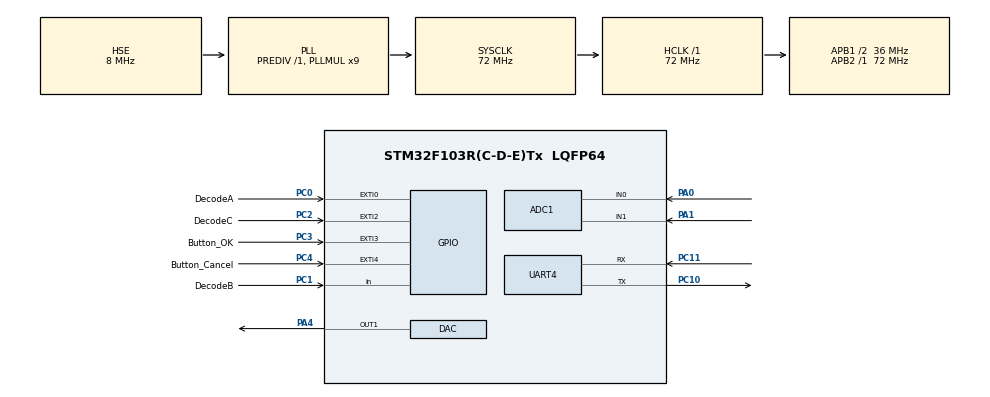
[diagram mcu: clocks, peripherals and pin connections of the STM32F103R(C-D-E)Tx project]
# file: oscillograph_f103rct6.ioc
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ADC1.Channel-0\#ChannelRegularConversion=ADC_CHANNEL_0
ADC1.Channel-1\#ChannelRegularConversion=ADC_CHANNEL_1
ADC1.ExternalTrigConv=ADC_EXTERNALTRIGCONV_T3_TRGO
ADC1.NbrOfConversion=2
ADC1.NbrOfConversionFlag=1
ADC1.Rank-0\#ChannelRegularConversion=1
ADC1.Rank-1\#ChannelRegularConversion=2
ADC1.SamplingTime-0\#ChannelRegularConversion=ADC_SAMPLETIME_1CYCLE_5
ADC1.SamplingTime-1\#ChannelRegularConversion=ADC_SAMPLETIME_1CYCLE_5
ADC1.master=1
DAC.DAC_Trigger=DAC_TRIGGER_T4_TRGO
Dma.ADC1.0.Direction=DMA_PERIPH_TO_MEMORY
Dma.ADC1.0.Instance=DMA1_Channel1
Dma.ADC1.0.MemDataAlignment=DMA_MDATAALIGN_HALFWORD
Dma.ADC1.0.MemInc=DMA_MINC_ENABLE
Dma.ADC1.0.Mode=DMA_CIRCULAR
Dma.ADC1.0.PeriphDataAlignment=DMA_PDATAALIGN_HALFWORD
Dma.ADC1.0.PeriphInc=DMA_PINC_DISABLE
Dma.ADC1.0.Priority=DMA_PRIORITY_LOW
Dma.DAC_CH1.1.Direction=DMA_MEMORY_TO_PERIPH
Dma.DAC_CH1.1.Instance=DMA2_Channel3
Dma.DAC_CH1.1.MemDataAlignment=DMA_MDATAALIGN_HALFWORD
Dma.DAC_CH1.1.MemInc=DMA_MINC_ENABLE
Dma.DAC_CH1.1.Mode=DMA_CIRCULAR
Dma.DAC_CH1.1.PeriphDataAlignment=DMA_PDATAALIGN_HALFWORD
Dma.DAC_CH1.1.PeriphInc=DMA_PINC_DISABLE
Dma.DAC_CH1.1.Priority=DMA_PRIORITY_LOW
Dma.Request0=ADC1
Dma.Request1=DAC_CH1
Mcu.Family=STM32F1
Mcu.Name=STM32F103R(C-D-E)Tx
Mcu.Package=LQFP64
NVIC.ADC1_2_IRQn=true\:0\:0\:false\:false\:true\:true\:true\:true
NVIC.DMA1_Channel1_IRQn=true\:0\:0\:false\:false\:true\:false\:true\:true
NVIC.DMA2_Channel3_IRQn=true\:0\:0\:false\:false\:true\:false\:true\:true
NVIC.EXTI0_IRQn=true\:1\:0\:true\:false\:true\:true\:true\:true
NVIC.EXTI2_IRQn=true\:1\:0\:true\:false\:true\:true\:true\:true
NVIC.EXTI3_IRQn=true\:1\:0\:true\:false\:true\:true\:true\:true
NVIC.EXTI4_IRQn=true\:1\:0\:true\:false\:true\:true\:true\:true
NVIC.PriorityGroup=NVIC_PRIORITYGROUP_4
NVIC.TIM3_IRQn=true\:0\:0\:false\:false\:true\:true\:true\:true
NVIC.TIM4_IRQn=true\:0\:0\:false\:false\:true\:true\:true\:true
NVIC.UART4_IRQn=true\:0\:0\:false\:false\:true\:true\:true\:true
PA0-WKUP.Signal=ADCx_IN0
PA1.Signal=ADCx_IN1
PA4.Signal=COMP_DAC1_group
PC0.GPIO_Label=DecodeA
PC0.GPIO_PuPd=GPIO_PULLDOWN
PC0.Signal=GPXTI0
PC1.GPIO_Label=DecodeB
PC1.GPIO_PuPd=GPIO_PULLDOWN
PC1.Signal=GPIO_Input
PC10.Mode=Asynchronous
PC10.Signal=UART4_TX
PC11.Mode=Asynchronous
PC11.Signal=UART4_RX
PC14-OSC32_IN.Mode=LSE-External-Oscillator
PC14-OSC32_IN.Signal=RCC_OSC32_IN
PC15-OSC32_OUT.Mode=LSE-External-Oscillator
PC15-OSC32_OUT.Signal=RCC_OSC32_OUT
PC2.GPIO_Label=DecodeC
PC2.GPIO_ModeDefaultEXTI=GPIO_MODE_IT_RISING
PC2.GPIO_PuPd=GPIO_PULLUP
PC2.Signal=GPXTI2
PC3.GPIO_Label=Button_OK
PC3.GPIO_ModeDefaultEXTI=GPIO_MODE_IT_FALLING
PC3.GPIO_PuPd=GPIO_PULLUP
PC3.Signal=GPXTI3
PC4.GPIO_Label=Button_Cancel
PC4.GPIO_ModeDefaultEXTI=GPIO_MODE_IT_FALLING
PC4.GPIO_PuPd=GPIO_PULLUP
PC4.Signal=GPXTI4
PD0-OSC_IN.Mode=HSE-External-Oscillator
PD0-OSC_IN.Signal=RCC_OSC_IN
PD1-OSC_OUT.Mode=HSE-External-Oscillator
PD1-OSC_OUT.Signal=RCC_OSC_OUT
ProjectManager.HeapSize=0x200
ProjectManager.StackSize=0x400
ProjectManager.TargetToolchain=MDK-ARM V5.32
RCC.ADCPresc=RCC_ADCPCLK2_DIV6
RCC.AHBFreq_Value=72000000
RCC.APB1CLKDivider=RCC_HCLK_DIV2
RCC.APB1Freq_Value=36000000
RCC.APB1TimFreq_Value=72000000
RCC.APB2Freq_Value=72000000
RCC.APB2TimFreq_Value=72000000
RCC.HCLKFreq_Value=72000000
RCC.PLLMUL=RCC_PLL_MUL9
RCC.PLLSourceVirtual=RCC_PLLSOURCE_HSE
RCC.SYSCLKFreq_VALUE=72000000
RCC.SYSCLKSource=RCC_SYSCLKSOURCE_PLLCLK
RCC.USBFreq_Value=72000000
SH.ADCx_IN0.0=ADC1_IN0,IN0
SH.ADCx_IN1.0=ADC1_IN1,IN1
SH.COMP_DAC1_group.0=DAC_OUT1,DAC_OUT1
TIM3.AutoReloadPreload=TIM_AUTORELOAD_PRELOAD_ENABLE
TIM3.Period=10000-1
TIM3.Prescaler=7200-1
TIM3.TIM_MasterOutputTrigger=TIM_TRGO_UPDATE
TIM4.AutoReloadPreload=TIM_AUTORELOAD_PRELOAD_ENABLE
TIM4.Period=10000-1
TIM4.Prescaler=7200-1
TIM4.TIM_MasterOutputTrigger=TIM_TRGO_UPDATE
UART4.VirtualMode=Asynchronous
VP_SYS_VS_ND.Mode=No_Debug
VP_TIM3_VS_ClockSourceINT.Mode=Internal
VP_TIM4_VS_ClockSourceINT.Mode=Internal
board=custom

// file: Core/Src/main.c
/* USER CODE BEGIN Header */
/**
 ******************************************************************************
 * @file           : main.c
 * @brief          : Main program body
 ******************************************************************************
 * @attention
 *
 * Copyright (c) 2023 STMicroelectronics.
 * All rights reserved.
 *
 * This software is licensed under terms that can be found in the LICENSE file
 * in the root directory of this software component.
 * If no LICENSE file comes with this software, it is provided AS-IS.
 *
 ******************************************************************************
 */
/* USER CODE END Header */
#include "main.h"
#include "adc.h"
#include "dac.h"
#include "dma.h"
#include "tim.h"
#include "usart.h"
#include "gpio.h"

/* USER CODE BEGIN Includes */
#include "test.h"
#include "app.h"
#include "stdio.h"
#include "stm32f1xx_it.h"
/* USER CODE END Includes */

void SystemClock_Config(void);

int main(void)
{

  /* MCU Configuration--------------------------------------------------------*/

  /* Reset of all peripherals, Initializes the Flash interface and the Systick. */
  HAL_Init();

  /* Configure the system clock */
  SystemClock_Config();

  /* Initialize all configured peripherals */
  MX_GPIO_Init();
  MX_DMA_Init();
  MX_ADC1_Init();
  MX_DAC_Init();
  MX_TIM3_Init();
  MX_TIM4_Init();
  MX_UART4_Init();

  /* Infinite loop */
  /* USER CODE BEGIN WHILE */
	LCD_Init();
  APP_Init();

  while (1)
  {
    HAL_Delay(100);
    APP.Window_Resresh_Handler();
    EX_TI_Handler();
    /* USER CODE END WHILE */

  }
}

void SystemClock_Config(void)
{
  RCC_OscInitTypeDef RCC_OscInitStruct = {0};
  RCC_ClkInitTypeDef RCC_ClkInitStruct = {0};
  RCC_PeriphCLKInitTypeDef PeriphClkInit = {0};

  /** Initializes the RCC Oscillators according to the specified parameters
  * in the RCC_OscInitTypeDef structure.
  */
  RCC_OscInitStruct.OscillatorType = RCC_OSCILLATORTYPE_HSE;
  RCC_OscInitStruct.HSEState = RCC_HSE_ON;
  RCC_OscInitStruct.HSEPredivValue = RCC_HSE_PREDIV_DIV1;
  RCC_OscInitStruct.HSIState = RCC_HSI_ON;
  RCC_OscInitStruct.PLL.PLLState = RCC_PLL_ON;
  RCC_OscInitStruct.PLL.PLLSource = RCC_PLLSOURCE_HSE;
  RCC_OscInitStruct.PLL.PLLMUL = RCC_PLL_MUL9;
  if (HAL_RCC_OscConfig(&RCC_OscInitStruct) != HAL_OK)
  {
    Error_Handler();
  }

  /** Initializes the CPU, AHB and APB buses clocks
  */
  RCC_ClkInitStruct.ClockType = RCC_CLOCKTYPE_HCLK|RCC_CLOCKTYPE_SYSCLK
                              |RCC_CLOCKTYPE_PCLK1|RCC_CLOCKTYPE_PCLK2;
  RCC_ClkInitStruct.SYSCLKSource = RCC_SYSCLKSOURCE_PLLCLK;
  RCC_ClkInitStruct.AHBCLKDivider = RCC_SYSCLK_DIV1;
  RCC_ClkInitStruct.APB1CLKDivider = RCC_HCLK_DIV2;
  RCC_ClkInitStruct.APB2CLKDivider = RCC_HCLK_DIV1;

  if (HAL_RCC_ClockConfig(&RCC_ClkInitStruct, FLASH_LATENCY_2) != HAL_OK)
  {
    Error_Handler();
  }
  PeriphClkInit.PeriphClockSelection = RCC_PERIPHCLK_ADC;
  PeriphClkInit.AdcClockSelection = RCC_ADCPCLK2_DIV6;
  if (HAL_RCCEx_PeriphCLKConfig(&PeriphClkInit) != HAL_OK)
  {
    Error_Handler();
  }
}

void Error_Handler(void)
{
  __disable_irq();
  while (1)
  {
  }
}
